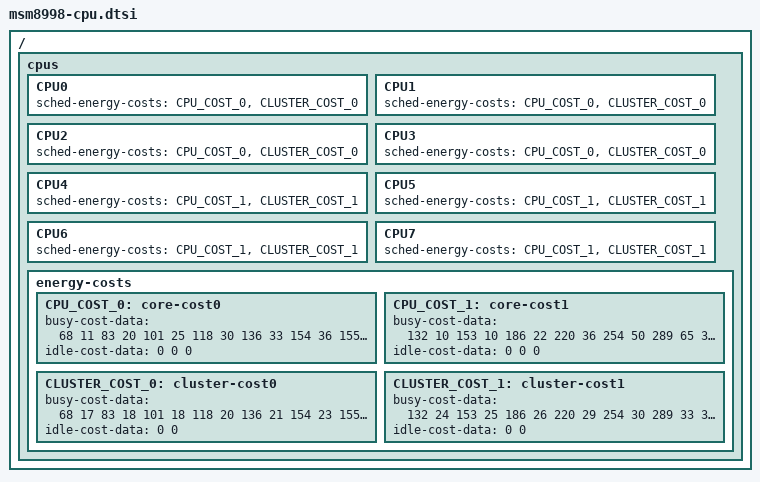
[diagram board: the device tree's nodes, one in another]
/* Copyright (c) 2015-2016, The Linux Foundation. All rights reserved.
 *
 * This program is free software; you can redistribute it and/or modify
 * it under the terms of the GNU General Public License version 2 and
 * only version 2 as published by the Free Software Foundation.
 *
 * This program is distributed in the hope that it will be useful,
 * but WITHOUT ANY WARRANTY; without even the implied warranty of
 * MERCHANTABILITY or FITNESS FOR A PARTICULAR PURPOSE.  See the
 * GNU General Public License for more details.
 */

/ {
	cpus {
		CPU0 {
			sched-energy-costs = <&CPU_COST_0 &CLUSTER_COST_0>;
		};
		CPU1 {
			sched-energy-costs = <&CPU_COST_0 &CLUSTER_COST_0>;
		};
		CPU2 {
			sched-energy-costs = <&CPU_COST_0 &CLUSTER_COST_0>;
		};
		CPU3 {
			sched-energy-costs = <&CPU_COST_0 &CLUSTER_COST_0>;
		};
		CPU4 {
			sched-energy-costs = <&CPU_COST_1 &CLUSTER_COST_1>;
		};
		CPU5 {
			sched-energy-costs = <&CPU_COST_1 &CLUSTER_COST_1>;
		};
		CPU6 {
			sched-energy-costs = <&CPU_COST_1 &CLUSTER_COST_1>;
		};
		CPU7 {
			sched-energy-costs = <&CPU_COST_1 &CLUSTER_COST_1>;
		};
		energy-costs {
			CPU_COST_0: core-cost0 {
				busy-cost-data = <
					68  11
					83  20
					101 25
					118 30
					136 33
					154 36
					155 36
					189 42
					203 47
					220 54
					239 62
					226 67
					270 73
					287 79
					305 88
					322 95
					342 104
					358 111
					385 134
					402 155
					420 178
					438 201
				>;
				idle-cost-data = <
					0 0 0
				>;
			};
			CPU_COST_1: core-cost1 {
				busy-cost-data = <
					132  10
					153  10
					186  22
					220  36
					254  50
					289  65
					323  78
					357  91
					400  109
					435  122
					467  136
					502  154
					528  176
					561  206
					596  241
					630  282
					664  318
					698  365
					733  418
					767  472
					800  548
					833  626
					869  721
					903  837
					938  965
					1020 1103
					1024 1102
				>;
				idle-cost-data = <
				      0 0 0
				>;
			};
			CLUSTER_COST_0: cluster-cost0 {
				busy-cost-data = <
					68  17
					83  18
					101 18
					118 20
					136 21
					154 23
					155 23
					189 24
					203 27
					220 29
					239 30
					226 32
					270 33
					287 35
					305 38
					322 39
					342 42
					358 46
					385 48
					402 53
					420 59
					438 66
				>;
				idle-cost-data = <
					0
					0
				>;
			};
			CLUSTER_COST_1: cluster-cost1 {
				busy-cost-data = <
					132  24
					153  25
					186  26
					220  29
					254  30
					289  33
					323  35
					357  37
					400  38
					435  40
					467  43
					502  44
					528  46
					561  50
					596  54
					630  60
					664  63
					698  70
					733  74
					767  80
					800  87
					833  96
					869  104
					903  120
					938  130
					1020 203
					1024 203
				>;
				idle-cost-data = <
					0
					0
				>;
			};
		};
	};
};
